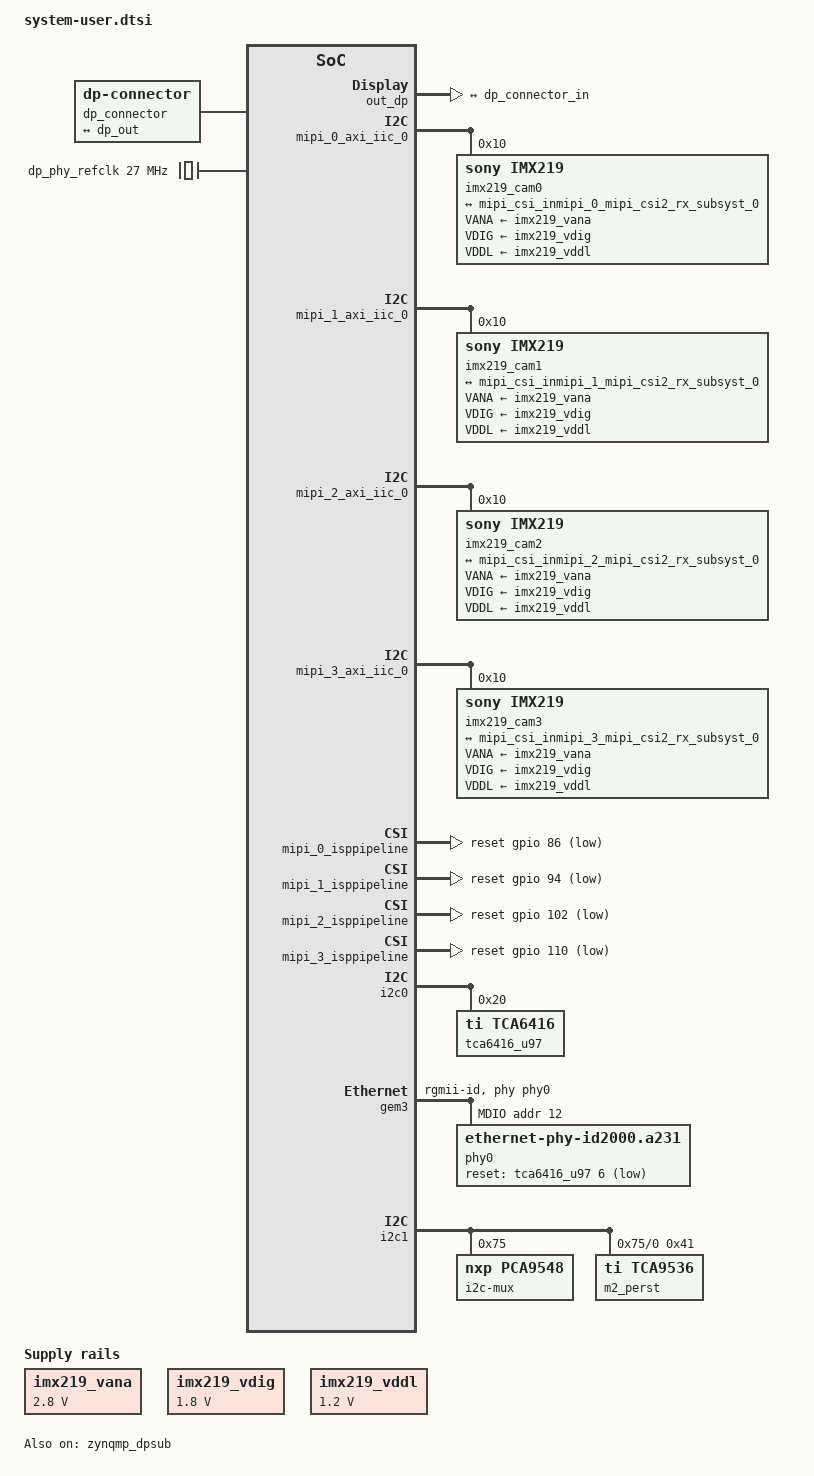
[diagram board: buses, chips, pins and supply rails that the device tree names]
/include/ "system-conf.dtsi"
/ {
	dp_aclk: dp_aclk {
		compatible = "fixed-clock";
		#clock-cells = <0>;
		clock-frequency = <100000000>;
		clock-accuracy = <100>;
	};

	/* Repairing misc_clks as per Article number 000036480 */
	/delete-node/ misc_clk_0;
	misc_clk_0: misc_clk_0 {
		#clock-cells = <0>;
		clock-frequency = <99999000>;
		compatible = "fixed-clock";
	};

	/delete-node/ misc_clk_1;
	misc_clk_1: misc_clk_1 {
		#clock-cells = <0>;
		clock-frequency = <249997500>;
		compatible = "fixed-clock";
	};

	/delete-node/ misc_clk_2;
	misc_clk_2: misc_clk_2 {
		#clock-cells = <0>;
		clock-frequency = <199998000>;
		compatible = "fixed-clock";
	};

	/delete-node/ misc_clk_3;
	misc_clk_3: misc_clk_3 {
		#clock-cells = <0>;
		clock-frequency = <49999500>;
		compatible = "fixed-clock";
	};
};

&zynqmp_dpsub {
    status = "okay";
    clocks = <&dp_aclk>,<&zynqmp_clk DP_AUDIO_REF>,<&zynqmp_clk DP_VIDEO_REF>,<&display_pipeline_clk_wiz_0 0>;
    clock-names = "dp_apb_clk", "dp_aud_clk","dp_vtc_pixel_clk_in","dp_live_video_in_clk";
    xlnx,bridge = <&display_pipeline_v_tc_0>;
};

/*
 * 2025.2 zynqmp-dpsub requires endpoints inside the auto-generated
 * &zynqmp_dpsub/ports/port@N children, not as stray port@0 nodes at the
 * dpsub root. Wire live_video (port@0) <-> v_mix CRTC and out_dp (port@5)
 * <-> dp-connector so the driver sees the live-video input and DP output
 * as connected.
 */
&live_video {
    dp_encoder: endpoint {
        remote-endpoint = <&mixer_crtcdisplay_pipeline_v_mix_0>;
    };
};

&out_dp {
    dp_out: endpoint {
        remote-endpoint = <&dp_connector_in>;
    };
};

/ {
    dp_connector: dp-connector {
        compatible = "dp-connector";
        type = "full-size";
        port {
            dp_connector_in: endpoint {
                remote-endpoint = <&dp_out>;
            };
        };
    };

    /*
     * PSGTR ref clock for DP. The auto-generated pcw.dtsi references
     * refclk 3 (xlnx,phys = <&psgtr X 6 X 3>) but doesn't declare any
     * clocks on the psgtr node, so xpsgtr_xlate rejects refclk 3 with
     * "Invalid reference clock number 3" and DP probe fails with -EINVAL.
     * Declare a fixed-clock at 27 MHz (the DP refclk rate FSBL programs
     * the on-board Si5341 to output) so the SSC lookup matches.
     */
    dp_phy_refclk: dp_phy_refclk {
        compatible = "fixed-clock";
        #clock-cells = <0>;
        clock-frequency = <27000000>;
    };
};

&psgtr {
    clocks = <&dp_phy_refclk>;
    clock-names = "ref3";
};

&amba_pl {
	imx219_clk: imx219_clk {
		#clock-cells = <0x0>;
		clock-frequency = <24000000>;
		compatible = "fixed-clock";
	};


	imx219_vana: fixedregulator@3 {
		compatible = "regulator-fixed";
		regulator-name = "imx219_vana";
		regulator-min-microvolt = <2800000>;
		regulator-max-microvolt = <2800000>;
		enable-active-high;
	};

	imx219_vdig: fixedregulator@4 {
		compatible = "regulator-fixed";
		regulator-name = "imx219_vdig";
		regulator-min-microvolt = <1800000>;
		regulator-max-microvolt = <1800000>;
	};

	imx219_vddl: fixedregulator@5 {
		compatible = "regulator-fixed";
		regulator-name = "imx219_vddl";
		regulator-min-microvolt = <1200000>;
		regulator-max-microvolt = <1200000>;
	};
	
};

&mipi_0_axi_iic_0 {
	imx219_cam0: sensor@10 {
		compatible = "sony,imx219";
		reg = <0x10>;
		clocks = <&imx219_clk>;
		VANA-supply = <&imx219_vana>;   /* 2.8v */
		VDIG-supply = <&imx219_vdig>;   /* 1.8v */
		VDDL-supply = <&imx219_vddl>;   /* 1.2v */

		port {
		     imx219_cam0_0: endpoint {
			remote-endpoint = <&mipi_csi_inmipi_0_mipi_csi2_rx_subsyst_0>;
			data-lanes = <1 2>;
			link-frequencies = /bits/ 64 <456000000>;
			};
		};
	};
};

&mipi_1_axi_iic_0 {
	imx219_cam1: sensor@10 {
		compatible = "sony,imx219";
		reg = <0x10>;
		clocks = <&imx219_clk>;
		VANA-supply = <&imx219_vana>;   /* 2.8v */
		VDIG-supply = <&imx219_vdig>;   /* 1.8v */
		VDDL-supply = <&imx219_vddl>;   /* 1.2v */

		port {
		     imx219_cam1_0: endpoint {
			remote-endpoint = <&mipi_csi_inmipi_1_mipi_csi2_rx_subsyst_0>;
			data-lanes = <1 2>;
			link-frequencies = /bits/ 64 <456000000>;
			};
		};
	};
};

&mipi_2_axi_iic_0 {
	imx219_cam2: sensor@10 {
		compatible = "sony,imx219";
		reg = <0x10>;
		clocks = <&imx219_clk>;
		VANA-supply = <&imx219_vana>;   /* 2.8v */
		VDIG-supply = <&imx219_vdig>;   /* 1.8v */
		VDDL-supply = <&imx219_vddl>;   /* 1.2v */

		port {
		     imx219_cam2_0: endpoint {
			remote-endpoint = <&mipi_csi_inmipi_2_mipi_csi2_rx_subsyst_0>;
			data-lanes = <1 2>;
			link-frequencies = /bits/ 64 <456000000>;
			};
		};
	};
};

&mipi_3_axi_iic_0 {
	imx219_cam3: sensor@10 {
		compatible = "sony,imx219";
		reg = <0x10>;
		clocks = <&imx219_clk>;
		VANA-supply = <&imx219_vana>;   /* 2.8v */
		VDIG-supply = <&imx219_vdig>;   /* 1.8v */
		VDDL-supply = <&imx219_vddl>;   /* 1.2v */

		port {
		     imx219_cam3_0: endpoint {
			remote-endpoint = <&mipi_csi_inmipi_3_mipi_csi2_rx_subsyst_0>;
			data-lanes = <1 2>;
			link-frequencies = /bits/ 64 <456000000>;
			};
		};
	};
};

&mipi_0_mipi_csi2_rx_subsyst_0 {
	xlnx,en-active-lanes;
};

&mipi_1_mipi_csi2_rx_subsyst_0 {
	xlnx,en-active-lanes;
};

&mipi_2_mipi_csi2_rx_subsyst_0 {
	xlnx,en-active-lanes;
};

&mipi_3_mipi_csi2_rx_subsyst_0 {
	xlnx,en-active-lanes;
};

&mipi_csi_inmipi_0_mipi_csi2_rx_subsyst_0 {
	remote-endpoint = <&imx219_cam0_0>;
};

&mipi_csi_inmipi_1_mipi_csi2_rx_subsyst_0 {
	remote-endpoint = <&imx219_cam1_0>;
};

&mipi_csi_inmipi_2_mipi_csi2_rx_subsyst_0 {
	remote-endpoint = <&imx219_cam2_0>;
};

&mipi_csi_inmipi_3_mipi_csi2_rx_subsyst_0 {
	remote-endpoint = <&imx219_cam3_0>;
};

&mipi_0_isppipeline {
	reset-gpios = <&gpio 86 1>;
	xlnx,max-height = /bits/ 16 <1232>;
	xlnx,max-width = /bits/ 16 <1920>;
	xlnx,rgain = /bits/ 16 <128>;
	xlnx,bgain = /bits/ 16 <210>;
	xlnx,pawb = /bits/ 16 <350>;
	xlnx,mode-reg = <1>;
};

&isppipeline_port0mipi_0_isppipeline {
	xlnx,video-width = <10>;
	xlnx,cfa-pattern = "rggb";
};

&isppipeline_port1mipi_0_isppipeline {
	xlnx,video-width = <8>;
	xlnx,cfa-pattern = "rggb";
};

&mipi_1_isppipeline {
	reset-gpios = <&gpio 94 1>;
	xlnx,max-height = /bits/ 16 <1232>;
	xlnx,max-width = /bits/ 16 <1920>;
	xlnx,rgain = /bits/ 16 <128>;
	xlnx,bgain = /bits/ 16 <210>;
	xlnx,pawb = /bits/ 16 <350>;
	xlnx,mode-reg = <1>;
};

&isppipeline_port0mipi_1_isppipeline {
	xlnx,video-width = <10>;
	xlnx,cfa-pattern = "rggb";
};

&isppipeline_port1mipi_1_isppipeline {
	xlnx,video-width = <8>;
	xlnx,cfa-pattern = "rggb";
};

&mipi_2_isppipeline {
	reset-gpios = <&gpio 102 1>;
	xlnx,max-height = /bits/ 16 <1232>;
	xlnx,max-width = /bits/ 16 <1920>;
	xlnx,rgain = /bits/ 16 <128>;
	xlnx,bgain = /bits/ 16 <210>;
	xlnx,pawb = /bits/ 16 <350>;
	xlnx,mode-reg = <1>;
};

&isppipeline_port0mipi_2_isppipeline {
	xlnx,video-width = <10>;
	xlnx,cfa-pattern = "rggb";
};

&isppipeline_port1mipi_2_isppipeline {
	xlnx,video-width = <8>;
	xlnx,cfa-pattern = "rggb";
};

&mipi_3_isppipeline {
	reset-gpios = <&gpio 110 1>;
	xlnx,max-height = /bits/ 16 <1232>;
	xlnx,max-width = /bits/ 16 <1920>;
	xlnx,rgain = /bits/ 16 <128>;
	xlnx,bgain = /bits/ 16 <210>;
	xlnx,pawb = /bits/ 16 <350>;
	xlnx,mode-reg = <1>;
};

&isppipeline_port0mipi_3_isppipeline {
	xlnx,video-width = <10>;
	xlnx,cfa-pattern = "rggb";
};

&isppipeline_port1mipi_3_isppipeline {
	xlnx,video-width = <8>;
	xlnx,cfa-pattern = "rggb";
};

&mipi_0_v_proc {
	compatible = "xlnx,v-vpss-scaler-2.2";
};

&mipi_1_v_proc {
	compatible = "xlnx,v-vpss-scaler-2.2";
};

&mipi_2_v_proc {
	compatible = "xlnx,v-vpss-scaler-2.2";
};

&mipi_3_v_proc {
	compatible = "xlnx,v-vpss-scaler-2.2";
};

&display_pipeline_clk_wiz_0 {
	#address-cells = <2>;
};

&mixer_crtcdisplay_pipeline_v_mix_0 {
	remote-endpoint = <&dp_encoder>;
};

&display_pipeline_v_mix_0 {
	xlnx,disp-bridge = <&zynqmp_dpsub>;
	/* 2025.2 xlnx-mixer driver requires xlnx,bridge (VTC timing bridge)
	 * and xlnx,video-format (0=RGB, 1=YUV444, 2=YUV422) on the v_mix
	 * node, otherwise probe fails. Primary layer is NV16, so output is
	 * YUV422. */
	xlnx,bridge = <&display_pipeline_v_tc_0>;
	xlnx,video-format = <2>;
};

&display_pipeline_v_tc_0 {
	compatible = "xlnx,bridge-v-tc-6.1";
	xlnx,pixels-per-clock = <1>;
};

&mipi_csi_port1mipi_0_mipi_csi2_rx_subsyst_0 {
	xlnx,cfa-pattern = "rggb";
	xlnx,video-format = <12>;
	xlnx,video-width = <8>;
};

&mipi_csi_port0mipi_0_mipi_csi2_rx_subsyst_0 {
	xlnx,cfa-pattern = "rggb";
	xlnx,video-format = <12>;
	xlnx,video-width = <8>;
};

&mipi_csi_port1mipi_1_mipi_csi2_rx_subsyst_0 {
	xlnx,cfa-pattern = "rggb";
	xlnx,video-format = <12>;
	xlnx,video-width = <8>;
};

&mipi_csi_port0mipi_1_mipi_csi2_rx_subsyst_0 {
	xlnx,cfa-pattern = "rggb";
	xlnx,video-format = <12>;
	xlnx,video-width = <8>;
};

&mipi_csi_port1mipi_2_mipi_csi2_rx_subsyst_0 {
	xlnx,cfa-pattern = "rggb";
	xlnx,video-format = <12>;
	xlnx,video-width = <8>;
};

&mipi_csi_port0mipi_2_mipi_csi2_rx_subsyst_0 {
	xlnx,cfa-pattern = "rggb";
	xlnx,video-format = <12>;
	xlnx,video-width = <8>;
};

&mipi_csi_port1mipi_3_mipi_csi2_rx_subsyst_0 {
	xlnx,cfa-pattern = "rggb";
	xlnx,video-format = <12>;
	xlnx,video-width = <8>;
};

&mipi_csi_port0mipi_3_mipi_csi2_rx_subsyst_0 {
	xlnx,cfa-pattern = "rggb";
	xlnx,video-format = <12>;
	xlnx,video-width = <8>;
};


/* 2025.2 gen-machineconf assigns port-number=0 to uart1, making ttyPS0 map
 * to uart1. Vitis bsp.yaml confirms this board uses psu_uart_0, so force
 * ttyPS0 back to uart0. */
&uart0 {
   port-number = <0>;
};
&uart1 {
   port-number = <1>;
};
/ {
   aliases {
      serial0 = &uart0;
      serial1 = &uart1;
   };
   chosen {
      stdout-path = "serial0:115200n8";
   };
};

/* PCIe BAR fix (zcu106_hpc0, dual-PCIe): declare BOTH XDMA BARs (0xb0000000 and
 * 0xb8000000, 128 MB each) as NON-prefetchable 32-bit memory. The auto-generated
 * DT marks them prefetchable, which leaves the multi-BAR M.2 accelerators'
 * non-prefetchable BARs (e.g. DeepX M1 / MemryX BAR2/3/4/5) with nowhere to be
 * assigned, so the endpoint driver's BAR remap fails. The prefetchable 64-bit
 * BAR0s (0x540000000 and 0x550000000, 256 MB) are kept.
 *
 * NOTE: this file is a full copy of bsp/zcu106/.../system-user.dtsi plus the
 * axi-pcie@b8000000 override below (base single-PCIe zcu106 has no second root
 * port). Keep the shared portion in sync with the base zcu106 DT. */
&{/pl-bus/axi-pcie@b0000000} {
    ranges = <0x02000000 0x00 0xb0000000 0x00 0xb0000000 0x00 0x08000000   /* NON-pref 32-bit, 128 MB */
              0x43000000 0x05 0x40000000 0x05 0x40000000 0x00 0x10000000>; /* pref 64-bit, 256 MB  existing */
};

&{/pl-bus/axi-pcie@b8000000} {
    ranges = <0x02000000 0x00 0xb8000000 0x00 0xb8000000 0x00 0x08000000   /* NON-pref 32-bit, 128 MB */
              0x43000000 0x05 0x50000000 0x05 0x50000000 0x00 0x10000000>; /* pref 64-bit, 256 MB  existing */
};

/* Ethernet fix. The auto-generated DT does not wire up the ZCU106's GEM3 PHY
 * (TI DP83867 at MDIO 0x0c) or its reset line, so the interface comes up with a
 * random MAC and no usable PHY. On the ZCU106 the PHY reset (GEM3_EXP_RESET_B)
 * is line 6 of the on-board TCA6416 (U97), which sits DIRECTLY on PS I2C0 (no
 * mux) -- unlike the ZCU104, where U97 is behind the I2C1 -> TCA9548A mux.
 * Values mirror the stock zynqmp-zcu106-revA board DT.
 * (NOTE: keep this block in sync with the base bsp/zcu106 copy of this file.) */
&i2c0 {
    #address-cells = <1>;
    #size-cells = <0>;

    tca6416_u97: gpio@20 {
        compatible = "ti,tca6416";
        reg = <0x20>;
        gpio-controller;
        #gpio-cells = <2>;
        /* line 6 = GEM3_EXP_RESET_B; lines 10/11 = FMC_HPC0/HPC1_PRSNT_M2C_B */
    };
};

&gem3 {
    phy-handle = <&phy0>;
    phy-mode = "rgmii-id";
    mdio {
        #address-cells = <1>;
        #size-cells = <0>;
        phy0: ethernet-phy@c {
            compatible = "ethernet-phy-id2000.a231", "ti,dp83867";
            reg = <0xc>;
            ti,rx-internal-delay = <0x8>;
            ti,tx-internal-delay = <0xa>;
            ti,fifo-depth = <0x1>;
            ti,dp83867-rxctrl-strap-quirk;
            reset-gpios = <&tca6416_u97 6 GPIO_ACTIVE_LOW>;
        };
    };
};

/* M.2 Stack FMC I2C I/O expander (zcu106_hpc0, HPC0 slot).
 * On the ZCU106 the FMC HPC0 I2C (HPC0_IIC) is behind PS I2C1 -> PCA9548 (U135)
 * @ 0x75 -> channel 0 -- a different path than the ZCU104 (mux@74 ch4/select
 * 0x20). Describe that mux path and hang the M.2 M-key Stack FMC's TCA9536
 * (@ 0x41) off it, so Linux sees the expander and holds PERST# deasserted.
 *
 * NOTE: this DT node alone does NOT enable PCIe enumeration -- PERST# must be
 * deasserted BEFORE Linux probes the root complex, i.e. in the FSBL. The ZCU106
 * ps_i2c FSBL PERST# hook (I2C1 -> PCA9548 0x75 ch0 -> TCA9536 0x41) is still
 * TODO; until it exists, the gpio-hog below only holds PERST# high once Linux +
 * the i2c/tca9536 drivers are up (too late for enumeration). */
&i2c1 {
    #address-cells = <1>;
    #size-cells = <0>;

    i2c-mux@75 {
        compatible = "nxp,pca9548";  /* U135 @ 0x75 on PS I2C1 (FMC/board mux) */
        #address-cells = <1>;
        #size-cells = <0>;
        reg = <0x75>;

        i2c@0 {                      /* channel 0: HPC0_IIC (the M.2 Stack FMC bus) */
            #address-cells = <1>;
            #size-cells = <0>;
            reg = <0>;

            m2_perst: gpio@41 {
                compatible = "ti,tca9536";
                reg = <0x41>;
                gpio-controller;
                #gpio-cells = <2>;
                /* P0 = PERST_A# (M.2 slot A), P1 = PERST_B# (M.2 slot B)
                 *   -> HIGH = module operational, LOW = held in reset.
                 * P2 = PRSNT_M2C_L (input, active low). Per OP073 truth table. */
                m2-perst-hog {
                    gpio-hog;
                    gpios = <0 GPIO_ACTIVE_HIGH>, <1 GPIO_ACTIVE_HIGH>;
                    output-high;
                    line-name = "m2-perst";
                };
            };
        };
    };
};
